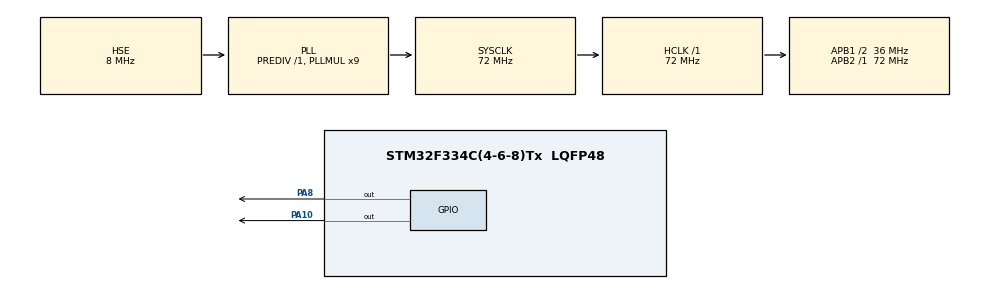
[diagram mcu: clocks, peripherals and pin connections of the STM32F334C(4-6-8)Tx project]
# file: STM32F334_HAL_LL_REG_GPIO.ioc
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Mcu.Family=STM32F3
Mcu.Name=STM32F334C(4-6-8)Tx
Mcu.Package=LQFP48
NVIC.PriorityGroup=NVIC_PRIORITYGROUP_4
PA10.GPIO_Speed=GPIO_SPEED_FREQ_HIGH
PA10.Signal=GPIO_Output
PA8.GPIO_Speed=GPIO_SPEED_FREQ_HIGH
PA8.Signal=GPIO_Output
PF0\ /\ OSC_IN.Mode=HSE-External-Clock-Source
PF0\ /\ OSC_IN.Signal=RCC_OSC_IN
ProjectManager.HeapSize=0x200
ProjectManager.StackSize=0x400
ProjectManager.TargetToolchain=STM32CubeIDE
RCC.AHBFreq_Value=72000000
RCC.APB1CLKDivider=RCC_HCLK_DIV2
RCC.APB1Freq_Value=36000000
RCC.APB1TimFreq_Value=72000000
RCC.APB2Freq_Value=72000000
RCC.APB2TimFreq_Value=72000000
RCC.CortexFreq_Value=72000000
RCC.HCLKFreq_Value=72000000
RCC.HSE_VALUE=8000000
RCC.HSI_VALUE=8000000
RCC.LSE_VALUE=32768
RCC.PLLMUL=RCC_PLL_MUL9
RCC.PLLSourceVirtual=RCC_PLLSOURCE_HSE
RCC.SYSCLKFreq_VALUE=72000000
RCC.SYSCLKSourceVirtual=RCC_SYSCLKSOURCE_PLLCLK
board=STM32F3348-DISCO

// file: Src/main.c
/* USER CODE BEGIN Header */
/**
  ******************************************************************************
  * @file           : main.c
  * @brief          : Main program body
  ******************************************************************************
  * @attention
  *
  * <h2><center>&copy; Copyright (c) 2019 STMicroelectronics.
  * All rights reserved.</center></h2>
  *
  * This software component is licensed by ST under BSD 3-Clause license,
  * the "License"; You may not use this file except in compliance with the
  * License. You may obtain a copy of the License at:
  *                        opensource.org/licenses/BSD-3-Clause
  *
  ******************************************************************************
  */
/* USER CODE END Header */

#include "main.h"

void SystemClock_Config(void);
static void MX_GPIO_Init(void);

int main(void)
{

  /* MCU Configuration--------------------------------------------------------*/

  /* Reset of all peripherals, Initializes the Flash interface and the Systick. */
  HAL_Init();

  /* Configure the system clock */
  SystemClock_Config();

  /* Initialize all configured peripherals */
  MX_GPIO_Init();

  /* Infinite loop */
  /* USER CODE BEGIN WHILE */
  while (1)
  {

	  // HAL = 878 KHz
//	  HAL_GPIO_WritePin(GPIOA, GPIO_PIN_8, GPIO_PIN_SET);
//	  HAL_GPIO_WritePin(GPIOA, GPIO_PIN_8, GPIO_PIN_RESET);

	  // HAL = 922 kHz
//	  HAL_GPIO_TogglePin(GPIOA, GPIO_PIN_8);

	  // LL = 1.18MHz
//	  LL_GPIO_SetOutputPin(GPIOA, LL_GPIO_PIN_8);
//	  LL_GPIO_ResetOutputPin(GPIOA, LL_GPIO_PIN_8);

	  // LL = 922 kHz
//	  LL_GPIO_TogglePin(GPIOA, LL_GPIO_PIN_8);

	  // http://hertaville.com/stm32f0-gpio-tutorial-part-1.html
	  // https://gist.github.com/iwalpola/6c36c9573fd322a268ce890a118571ca

	  // LL  = 3.78Mhz
	  // HAL = 3.78Mhz
//	  GPIOA->ODR |=  0x00000100;
//	  GPIOA->ODR &=  ~(0x00000100);

	  // LL  = 5.54Mhz
	  // HAL = 5.54Mhz
//	  GPIOA->BSRR = 0x00000100;
//	  GPIOA->BSRR = 0x01000000; // shift 16 bit to reset, see below

	  // HAL = 5.54Mhz
	  // LL  = 6.00Mhz
//	  GPIOA->BSRR = 0x00000100;
//	  GPIOA->BSRR = (0x00000100 << 16); // shift 16 bit to reset

	  // LL  = 5.54Mhz
	  // HAL = 5.54Mhz
//	  GPIOA->BSRR = (1<<8);
//	  GPIOA->BSRR = (1<<24);

	  // HAL = 5.54Mhz
	  // LL  = 6.00Mhz
	  GPIOA->BSRR = (1<<8); // Set
	  GPIOA->BRR = (1<<8); // Reset

    /* USER CODE END WHILE */

  }
}

void SystemClock_Config(void)
{
  RCC_OscInitTypeDef RCC_OscInitStruct = {0};
  RCC_ClkInitTypeDef RCC_ClkInitStruct = {0};

  /** Initializes the CPU, AHB and APB busses clocks
  */
  RCC_OscInitStruct.OscillatorType = RCC_OSCILLATORTYPE_HSE;
  RCC_OscInitStruct.HSEState = RCC_HSE_BYPASS;
  RCC_OscInitStruct.HSEPredivValue = RCC_HSE_PREDIV_DIV1;
  RCC_OscInitStruct.HSIState = RCC_HSI_ON;
  RCC_OscInitStruct.PLL.PLLState = RCC_PLL_ON;
  RCC_OscInitStruct.PLL.PLLSource = RCC_PLLSOURCE_HSE;
  RCC_OscInitStruct.PLL.PLLMUL = RCC_PLL_MUL9;
  if (HAL_RCC_OscConfig(&RCC_OscInitStruct) != HAL_OK)
  {
    Error_Handler();
  }
  /** Initializes the CPU, AHB and APB busses clocks
  */
  RCC_ClkInitStruct.ClockType = RCC_CLOCKTYPE_HCLK|RCC_CLOCKTYPE_SYSCLK
                              |RCC_CLOCKTYPE_PCLK1|RCC_CLOCKTYPE_PCLK2;
  RCC_ClkInitStruct.SYSCLKSource = RCC_SYSCLKSOURCE_PLLCLK;
  RCC_ClkInitStruct.AHBCLKDivider = RCC_SYSCLK_DIV1;
  RCC_ClkInitStruct.APB1CLKDivider = RCC_HCLK_DIV2;
  RCC_ClkInitStruct.APB2CLKDivider = RCC_HCLK_DIV1;

  if (HAL_RCC_ClockConfig(&RCC_ClkInitStruct, FLASH_LATENCY_2) != HAL_OK)
  {
    Error_Handler();
  }
}

static void MX_GPIO_Init(void)
{
  LL_GPIO_InitTypeDef GPIO_InitStruct = {0};

  /* GPIO Ports Clock Enable */
  LL_AHB1_GRP1_EnableClock(LL_AHB1_GRP1_PERIPH_GPIOF);
  LL_AHB1_GRP1_EnableClock(LL_AHB1_GRP1_PERIPH_GPIOA);

  /**/
  LL_GPIO_ResetOutputPin(GPIOA, LL_GPIO_PIN_8|LL_GPIO_PIN_10);

  /**/
  GPIO_InitStruct.Pin = LL_GPIO_PIN_8|LL_GPIO_PIN_10;
  GPIO_InitStruct.Mode = LL_GPIO_MODE_OUTPUT;
  GPIO_InitStruct.Speed = LL_GPIO_SPEED_FREQ_HIGH;
  GPIO_InitStruct.OutputType = LL_GPIO_OUTPUT_PUSHPULL;
  GPIO_InitStruct.Pull = LL_GPIO_PULL_NO;
  LL_GPIO_Init(GPIOA, &GPIO_InitStruct);

}

void Error_Handler(void)
{
}

/************************ (C) COPYRIGHT STMicroelectronics *****END OF FILE****/
